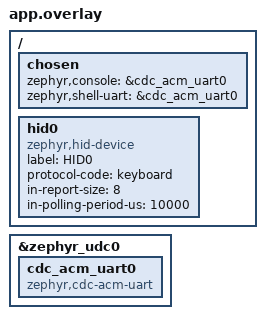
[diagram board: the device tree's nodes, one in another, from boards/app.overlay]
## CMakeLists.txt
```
cmake_minimum_required(VERSION 3.20)

list(APPEND EXTRA_ZEPHYR_MODULES "${CMAKE_CURRENT_SOURCE_DIR}/../../modules/rp2040_bootloader")
list(APPEND EXTRA_ZEPHYR_MODULES "${CMAKE_CURRENT_SOURCE_DIR}/../../modules/hid_keyboard")

set(DTC_OVERLAY_FILE "${CMAKE_CURRENT_SOURCE_DIR}/boards/app.overlay")
set(DTS_ROOT "${CMAKE_CURRENT_SOURCE_DIR}")

find_package(Zephyr REQUIRED HINTS $ENV{ZEPHYR_BASE})
project(my_cpp23_project)

# Use absolute pathing based on where this CMakeLists.txt lives
target_sources(app PRIVATE ${CMAKE_CURRENT_LIST_DIR}/src/main.cpp)
target_include_directories(app PRIVATE ${CMAKE_CURRENT_LIST_DIR}/../../modules/rp2040_bootloader/include)
target_include_directories(app PRIVATE ${CMAKE_CURRENT_LIST_DIR}/../../modules/hid_keyboard/include)

target_compile_features(app PUBLIC cxx_std_23)
```

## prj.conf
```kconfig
# Enable C++ Support
CONFIG_CPP=y
CONFIG_STD_CPP23=y
CONFIG_EXTERNAL_LIBCPP=y

# Use Newlib
CONFIG_NEWLIB_LIBC=y

# Generic Zephyr settings
CONFIG_GPIO=y

# UART console only - NO USB
CONFIG_USB_DEVICE_STACK_NEXT=y
CONFIG_USBD_CDC_ACM_CLASS=y
CONFIG_CDC_ACM_SERIAL_INITIALIZE_AT_BOOT=y
CONFIG_SERIAL=y
CONFIG_CONSOLE=y
CONFIG_UART_CONSOLE=y
CONFIG_UART_LINE_CTRL=y


# Shell
CONFIG_SHELL=y
CONFIG_DEVICE_SHELL=y

CONFIG_RP2040_BOOTLOADER=y

# Enable HID keyboard module
CONFIG_HID_KEYBOARD=y

# USB Device HID support
CONFIG_USBD_HID_SUPPORT=y
```

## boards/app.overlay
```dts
#include <zephyr/dt-bindings/pinctrl/rpi-pico-rp2040-pinctrl.h>

/ {
    chosen {
        zephyr,console = &cdc_acm_uart0;
        zephyr,shell-uart = &cdc_acm_uart0;
    };

    hid0: hid0 {
        compatible = "zephyr,hid-device";
        label = "HID0";
        protocol-code = "keyboard";
        in-report-size = <8>;
        in-polling-period-us = <10000>;
    };
};

&zephyr_udc0 {
    cdc_acm_uart0: cdc_acm_uart0 {
        compatible = "zephyr,cdc-acm-uart";
    };
};
```

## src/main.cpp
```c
#include <zephyr/kernel.h>
#include <zephyr/sys/printk.h>
#include <zephyr/drivers/gpio.h>

#include "bootloader_cmd.h"
#include "hid_keycodes.h"
#include "usb_hid_keyboard.h"
#include "zephyr/shell/shell.h"

int main(void)
{
    int timeout = 50;

    printk("[APP] Starting, waiting for HID (max 5s)...\n");
    while (!hid_keyboard_is_connected() && timeout > 0) {
        k_sleep(K_MSEC(100));
        timeout--;
    }

    if (hid_keyboard_is_connected()) {
        printk("[APP] HID connected!\n");
    } else {
        printk("[APP] HID NOT connected after timeout, trying anyway...\n");
    }

    int key_count = 0;
    while (true) {
        k_sleep(K_MSEC(5000));
        key_count++;

        printk("[APP] Sending key #%d...\n", key_count);
        int ret = hid_keyboard_send_key(HID_SCAN_AE_UPPER);
        printk("[APP] result=%d, connected=%d\n", ret, hid_keyboard_is_connected());

        k_sleep(K_MSEC(100));



        printk("[APP] Sending key #%d...\n", key_count);
        ret = hid_keyboard_send_key_with_mod(HID_SCAN_AE_LOWER, HID_MOD_LSHIFT);
        printk("[APP] result=%d, connected=%d\n", ret, hid_keyboard_is_connected());

        // printk("[APP] Sending key #%d...\n", key_count);
        // ret = hid_keyboard_send_key_with_mod(HID_KEY_A, HID_MOD_LSHIFT);
        // printk("[APP] result=%d, connected=%d\n", ret, hid_keyboard_is_connected());
    }

    (void)cmd_bootloader;
    return 0;
}
```
